AUTOSAR XML (schema 00044)
package /ComponentTypes
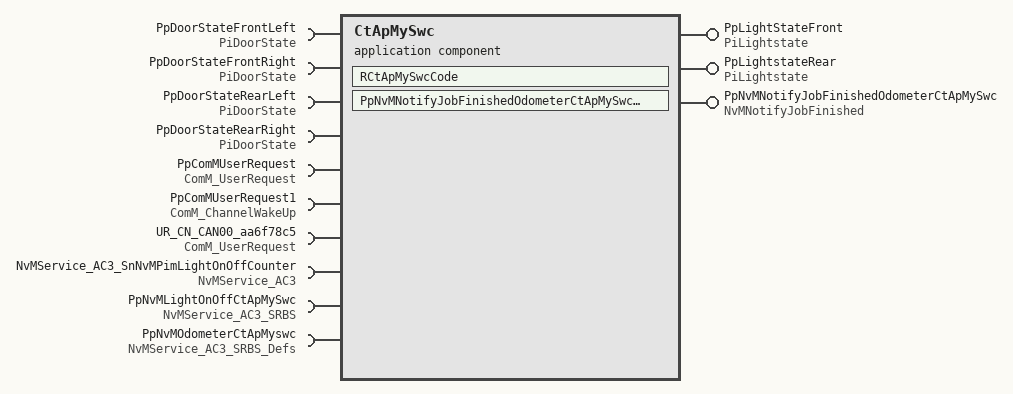
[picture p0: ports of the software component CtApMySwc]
  application sw component type CtApMySwc
    provide port PpLightStateFront: nonqueued-sender-com-spec{data-element=DeLightstate, init-value=constant-reference=Clightoff}, provided-interface=PiLightstate
    4 x require port, all with required-interface=PiDoorState:
      PpDoorStateFrontLeft: nonqueued-receiver-com-spec{data-element=DeDoorState, init-value=constant-reference=CDoorClosed}
      PpDoorStateFrontRight: nonqueued-receiver-com-spec{data-element=DeDoorState, init-value=constant-reference=CDoorClosed}
      PpDoorStateRearLeft: nonqueued-receiver-com-spec{data-element=DeDoorState, init-value=0}
      PpDoorStateRearRight: nonqueued-receiver-com-spec{data-element=DeDoorState, init-value=0}
    provide port PpLightstateRear: nonqueued-sender-com-spec{data-element=DeLightstate, init-value=0}, provided-interface=PiLightstate
    6 x require port:
      PpComMUserRequest: required-com-specs=[RequestComMode, GetCurrentComMode, GetMaxComMode, GetRequestedComMode], required-interface=ComM_UserRequest
      PpComMUserRequest1: required-com-specs=[PreventWakeUp, GetInhibitionStatus], required-interface=ComM_ChannelWakeUp
      UR_CN_CAN00_aa6f78c5: required-com-specs=[RequestComMode, GetCurrentComMode, GetMaxComMode, GetRequestedComMode], required-interface=ComM_UserRequest
      NvMService_AC3_SnNvMPimLightOnOffCounter: required-com-specs=[WriteBlock, ReadBlock, InvalidateNvBlock, GetErrorStatus, EraseBlock], required-interface=NvMService_AC3
      PpNvMLightOnOffCtApMySwc: required-com-specs=[WriteBlock, SetRamBlockStatus, ReadBlock, InvalidateNvBlock, GetErrorStatus, EraseBlock], required-interface=NvMService_AC3_SRBS
      PpNvMOdometerCtApMyswc: required-com-specs=[WriteBlock, SetRamBlockStatus, RestoreBlockDefaults, ReadBlock, InvalidateNvBlock, GetErrorStatus, EraseBlock], required-interface=NvMService_AC3_SRBS_Defs
    provide port PpNvMNotifyJobFinishedOdometerCtApMySwc: server-com-spec{operation=JobFinished, queue-length=1}, provided-interface=NvMNotifyJobFinished
    behavior CtApMySwc_InternalBehavior: data-type-mapping=DemoTypeMapping
      exclusive area ExArLightOnOffCounter
      exclusive area ExArOdometer
      ar-typed-per-instance-memorys:
        data PimOdometer: sw-calibration-access=READ-ONLY, type=AdtOdomter
        data PimLightOnOffCounter: sw-calibration-access=READ-ONLY, type=AdtLightstate
      4 x data received event, all with start-on-event=RCtApMySwcCode:
        DRT_RCtApMySwcCode_PpDoorStateFrontLeft_DeDoorState: data=PpDoorStateFrontLeft.DeDoorState
        DRT_RCtApMySwcCode_PpDoorStateFrontRight_DeDoorState: data=PpDoorStateFrontRight.DeDoorState
        DRT_RCtApMySwcCode_PpDoorStateRearLeft_DeDoorState: data=PpDoorStateRearLeft.DeDoorState
        DRT_RCtApMySwcCode_PpDoorStateRearRight_DeDoorState: data=PpDoorStateRearRight.DeDoorState
      operation invoked event OIT_PpNvMNotifyJobFinishedOdometerCtApMySwc_JobFinished_PpNvMNotifyJobFinishedOdometerCtApMySwc_JobFinished: start-on-event=PpNvMNotifyJobFinishedOdometerCtApMySwc_JobFinished, operation=PpNvMNotifyJobFinishedOdometerCtApMySwc.JobFinished
      explicit-inter-runnable-variables:
        data IrvDoorStateOld: type=AdtDoorState, init-value=constant-reference=CDoorClosed
      runnable RCtApMySwcCode: can-enter-exclusive-area=[ExArLightOnOffCounter, ExArOdometer]
        data-read-access:
          access READ_PpDoorStateRearLeft_DeDoorState: accessed-variable=PpDoorStateRearLeft.DeDoorState
        data-receive-point-by-arguments:
          access REC_PpDoorStateRearRight_DeDoorState: accessed-variable=PpDoorStateRearRight.DeDoorState
          access REC_PpDoorStateFrontLeft_DeDoorState: accessed-variable=PpDoorStateFrontLeft.DeDoorState
          access REC_PpDoorStateFrontRight_DeDoorState: accessed-variable=PpDoorStateFrontRight.DeDoorState
        data-send-points:
          access SEND_PpLightStateFront_DeLightstate: accessed-variable=PpLightStateFront.DeLightstate
          access SEND_PpLightstateRear_DeLightstate: accessed-variable=PpLightstateRear.DeLightstate
        read-local-variables:
          access Read_IrvDoorStateOld: accessed-variable=IrvDoorStateOld
        5 x sync call:
          SC_PpComMUserRequest_RequestComMode: operation=PpComMUserRequest.RequestComMode
          SC_PpComMUserRequest_GetRequestedComMode: operation=PpComMUserRequest.GetRequestedComMode
          SC_PpNvMLightOnOffCtApMySwc_WriteBlock: operation=PpNvMLightOnOffCtApMySwc.WriteBlock
          SC_PpNvMOdometerCtApMyswc_WriteBlock: operation=PpNvMOdometerCtApMyswc.WriteBlock
          SC_PpNvMOdometerCtApMyswc_GetErrorStatus: operation=PpNvMOdometerCtApMyswc.GetErrorStatus
        written-local-variables:
          access WRITE_IrvDoorStateOld: accessed-variable=IrvDoorStateOld
      runnable PpNvMNotifyJobFinishedOdometerCtApMySwc_JobFinished
      swc service dependency SnNvMPimOdometer
        assigned-datas:
          role=ramBlock, used-data-element=PimOdometer
          role=defaultValue, used-parameter-element=CalOdometer
        assigned-ports:
          port-prototype=PpNvMOdometerCtApMyswc, role=NvMService_AC3_SRBS_Defs
          port-prototype=PpNvMNotifyJobFinishedOdometerCtApMySwc, role=NvMNotifyJobFinished
        service-needs:
          nv block needs SnNvMPimOdometer: readonly=false, resistant-to-changed-sw=false, restore-at-start=true, store-at-shutdown=true, write-only-once=false
      swc service dependency SnNvMPimLightOnOffCounter: assigned-datas=role-based-data-assignment={role=ramBlock, used-data-element=PimLightOnOffCounter}, assigned-ports=role-based-port-assignment={port-prototype=PpNvMLightOnOffCtApMySwc, role=NvMService_AC3_SRBS}
        service-needs:
          nv block needs SnNvMPimLightOnOffCounter: readonly=false, resistant-to-changed-sw=false, restore-at-start=true, store-at-shutdown=true, write-only-once=false
      shared-parameters:
        parameter data prototype CalOdometer: sw-calibration-access=READ-WRITE, type=AdtOdomter, init-value=constant-reference=COdometerDefault
  swc implementation CtApMySwc_Implementation: behavior=CtApMySwc_InternalBehavior
